# STM32F401 register map
File version: 1.1
CPU: CM4 r1p0, little endian, no MPU, no FPU, 3 interrupt priority bits
Registers are 32-bit, read-write, reset 0x0 unless marked. A register's access mark holds for its fields unless they carry their own. Offsets are from the block's base; lines under a group give offsets from that group; [hi:lo] are bit positions; {n}, {i} and the like mark numbered series; 'fields as' and 'values as' point back to an identical list; <NAME> marks a mode.

## Memory map
0x40004400 USART2 size 0x400
0x40011000 USART1 size 0x400 — Universal synchronous asynchronous receiver transmitter
0x40020000 GPIOA size 0x400 — General-purpose I/Os
0x40020800 GPIOC size 0x400
0x40021C00 GPIOH size 0x400 — General-purpose I/Os
0x40023800 RCC size 0x400 — Reset and clock control

## Interrupts
25 TIM1_UP_TIM10 (GPIOC) — TIM1 Update interrupt and TIM10 global interrupt
28 TIM2 (GPIOA) — TIM2 global interrupt
31 I2C1_EV (RCC) — I2C1 event interrupt
32 I2C1_ER (RCC) — I2C1 error interrupt
42 OTG_FS_WKUP (USART1) — USB On-The-Go FS Wakeup through EXTI line interrupt
49 SDIO (GPIOH) — SDIO global interrupt
67 OTG_FS (USART1) — USB On The Go FS global interrupt

## GPIOA — General-purpose I/Os
Base 0x40020000
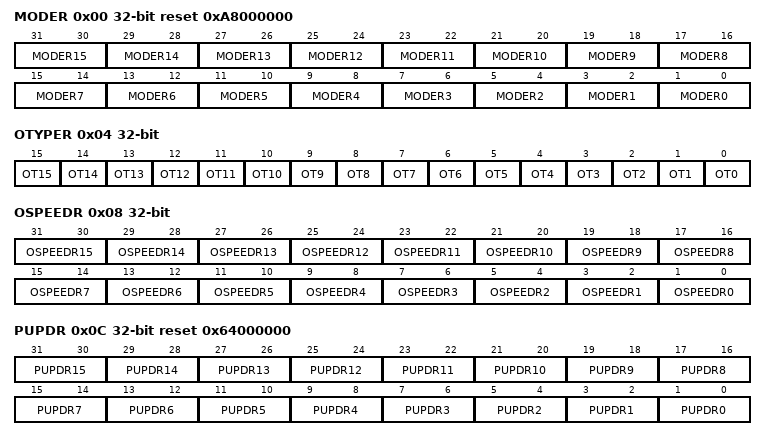
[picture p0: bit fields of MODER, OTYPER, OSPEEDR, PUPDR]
0x00 MODER reset 0xA8000000 — GPIO port mode register
  [2n+1:2n] MODER{n} (n=0..15) — Port x configuration bits (y = 0..15)
0x04 OTYPER — GPIO port output type register
  [n] OT{n} (n=0..15) — Port x configuration bits (y = 0..15)
0x08 OSPEEDR — GPIO port output speed register
  [2n+1:2n] OSPEEDR{n} (n=0..15) — Port x configuration bits (y = 0..15)
0x0C PUPDR reset 0x64000000 — GPIO port pull-up/pull-down register
  [2n+1:2n] PUPDR{n} (n=0..15) — Port x configuration bits (y = 0..15)
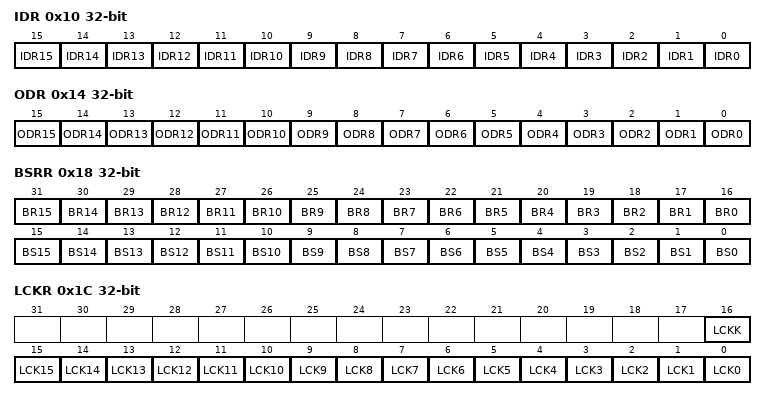
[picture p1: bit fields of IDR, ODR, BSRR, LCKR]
0x10 IDR ro — GPIO port input data register
  [n] IDR{n} (n=0..15) — Port input data (y = 0..15)
0x14 ODR — GPIO port output data register
  [n] ODR{n} (n=0..15) — Port output data (y = 0..15)
0x18 BSRR wo — GPIO port bit set/reset register
  [n+16] BR{n} (n=1..15) — Port x reset bit y (y = 0..15)
  [16] BR0 — Port x set bit y (y= 0..15)
  [n] BS{n} (n=0..15) — Port x set bit y (y= 0..15)
0x1C LCKR — GPIO port configuration lock register
  [16] LCKK — Port x lock bit y (y= 0..15)
  [n] LCK{n} (n=0..15) — Port x lock bit y (y= 0..15)
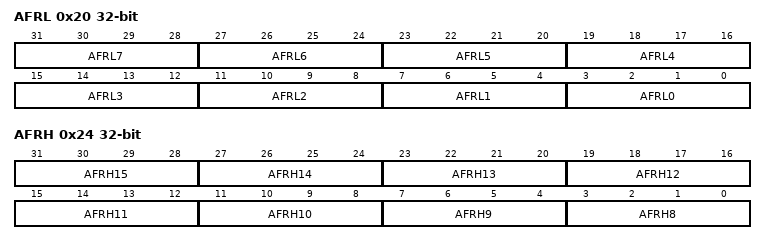
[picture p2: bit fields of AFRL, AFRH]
0x20 AFRL — GPIO alternate function low register
  [4n+3:4n] AFRL{n} (n=0..7) — Alternate function selection for port x bit y (y = 0..7)
0x24 AFRH — GPIO alternate function high register
  [4n-29:4n-32] AFRH{n} (n=8..15) — Alternate function selection for port x bit y (y = 8..15)

## GPIOH — General-purpose I/Os
Base 0x40021C00
Same registers: GPIOC 0x40020800
Registers as GPIOA; these are added or differ:
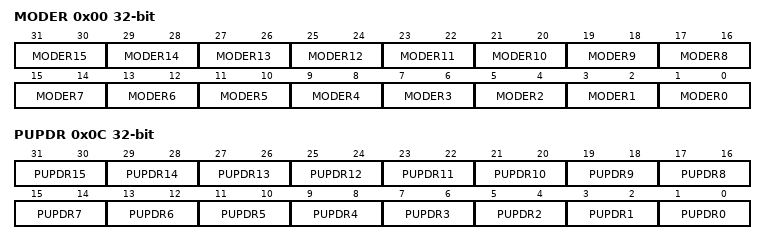
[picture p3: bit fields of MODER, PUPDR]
0x00 MODER — GPIO port mode register
  [2n+1:2n] MODER{n} (n=0..15) — Port x configuration bits (y = 0..15)
0x0C PUPDR — GPIO port pull-up/pull-down register
  [2n+1:2n] PUPDR{n} (n=0..15) — Port x configuration bits (y = 0..15)

## USART1 — Universal synchronous asynchronous receiver transmitter
Base 0x40011000
Same registers: USART2 0x40004400
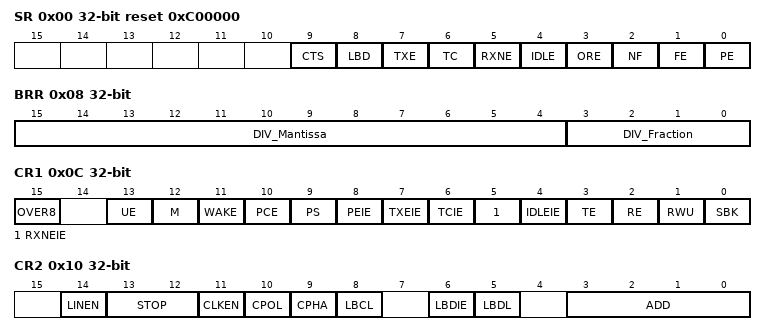
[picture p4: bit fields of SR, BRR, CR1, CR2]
0x00 SR access per field reset 0xC00000 — Status register
  [9] CTS rw — CTS flag
  [8] LBD rw — LIN break detection flag
  [7] TXE ro — Transmit data register empty
  [6] TC rw — Transmission complete
  [5] RXNE rw — Read data register not empty
  [4] IDLE ro — IDLE line detected
  [3] ORE ro — Overrun error
  [2] NF ro — Noise detected flag
  [1] FE ro — Framing error
  [0] PE ro — Parity error
0x04 DR — Data register
  [8:0] DR — Data value
0x08 BRR — Baud rate register
  [15:4] DIV_Mantissa — mantissa of USARTDIV
  [3:0] DIV_Fraction — fraction of USARTDIV
0x0C CR1 — Control register 1
  [15] OVER8 — Oversampling mode
  [13] UE — USART enable
  [12] M — Word length
  [11] WAKE — Wakeup method
  [10] PCE — Parity control enable
  [9] PS — Parity selection
  [8] PEIE — PE interrupt enable
  [7] TXEIE — TXE interrupt enable
  [6] TCIE — Transmission complete interrupt enable
  [5] RXNEIE — RXNE interrupt enable
  [4] IDLEIE — IDLE interrupt enable
  [3] TE — Transmitter enable
  [2] RE — Receiver enable
  [1] RWU — Receiver wakeup
  [0] SBK — Send break
0x10 CR2 — Control register 2
  [14] LINEN — LIN mode enable
  [13:12] STOP — STOP bits
  [11] CLKEN — Clock enable
  [10] CPOL — Clock polarity
  [9] CPHA — Clock phase
  [8] LBCL — Last bit clock pulse
  [6] LBDIE — LIN break detection interrupt enable
  [5] LBDL — lin break detection length
  [3:0] ADD — Address of the USART node
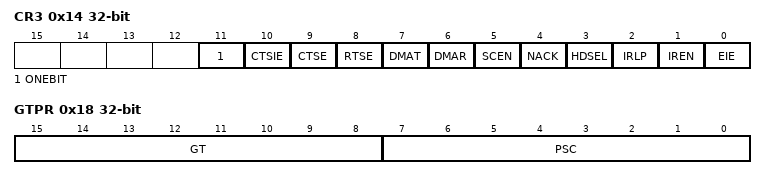
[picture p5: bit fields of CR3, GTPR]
0x14 CR3 — Control register 3
  [11] ONEBIT — One sample bit method enable
  [10] CTSIE — CTS interrupt enable
  [9] CTSE — CTS enable
  [8] RTSE — RTS enable
  [7] DMAT — DMA enable transmitter
  [6] DMAR — DMA enable receiver
  [5] SCEN — Smartcard mode enable
  [4] NACK — Smartcard NACK enable
  [3] HDSEL — Half-duplex selection
  [2] IRLP — IrDA low-power
  [1] IREN — IrDA mode enable
  [0] EIE — Error interrupt enable
0x18 GTPR — Guard time and prescaler register
  [15:8] GT — Guard time value
  [7:0] PSC — Prescaler value
